# LPC176x5x register map
File version: 0.2
CPU: CM3 r0p0, little endian, no MPU, no FPU, 0x5 interrupt priority bits, 0x0 interrupts
Registers are 32-bit, read-write, no defined reset value unless marked. A register's access mark holds for its fields unless they carry their own. Offsets are from the block's base; [hi:lo] are bit positions.

## EMAC — Ethernet
Base 0x50000000
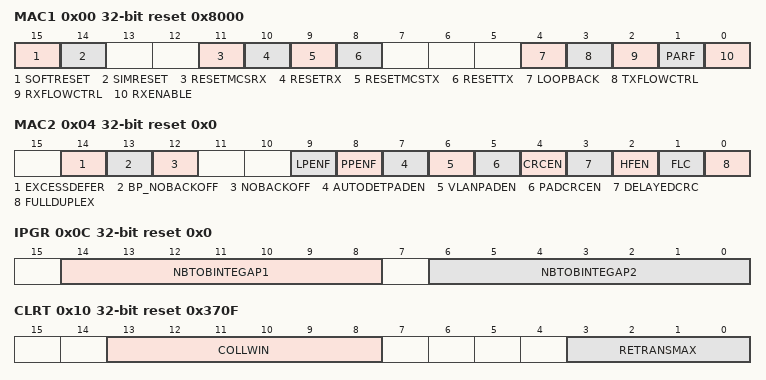
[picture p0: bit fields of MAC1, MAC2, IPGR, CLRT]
0x00 MAC1 reset 0x8000 — MAC configuration register 1.
  [15] SOFTRESET — SOFT RESET. Setting this bit will put all modules within the MAC in reset except the Host Interface.
  [14] SIMRESET — SIMULATION RESET. Setting this bit will cause a reset to the random number generator within the Transmit Function.
  [11] RESETMCSRX — Setting this bit resets the MAC Control Sublayer / Receive logic. The MCS logic implements flow control.
  [10] RESETRX — Setting this bit will put the Ethernet receive logic in reset.
  [9] RESETMCSTX — Setting this bit resets the MAC Control Sublayer / Transmit logic. The MCS logic implements flow control.
  [8] RESETTX — Setting this bit will put the Transmit Function logic in reset.
  [4] LOOPBACK — Setting this bit will cause the MAC Transmit interface to be looped back to the MAC Receive interface. Clearing this bit results in normal operation.
  [3] TXFLOWCTRL — TX FLOW CONTROL. When enabled (set to 1), PAUSE Flow Control frames are allowed to be transmitted. When disabled, Flow Control frames are blocked.
  [2] RXFLOWCTRL — RX FLOW CONTROL. When enabled (set to 1), the MAC acts upon received PAUSE Flow Control frames. When disabled, received PAUSE Flow Control frames are ignored.
  [1] PARF — PASS ALL RECEIVE FRAMES. When enabled (set to 1), the MAC will pass all frames regardless of type (normal vs. Control). When disabled, the MAC does not pass valid Control frames.
  [0] RXENABLE — RECEIVE ENABLE. Set this to allow receive frames to be received. Internally the MAC synchronizes this control bit to the incoming receive stream.
0x04 MAC2 reset 0x0 — MAC configuration register 2.
  [14] EXCESSDEFER — When enabled (set to 1) the MAC will defer to carrier indefinitely as per the Standard. When disabled, the MAC will abort when the excessive deferral limit is reached.
  [13] BP_NOBACKOFF — BACK PRESSURE / NO BACKOFF. When enabled (set to 1), after the MAC incidentally causes a collision during back pressure, it will immediately retransmit without backoff, reducing the chance of further collisions and ensuring transmit packets get sent.
  [12] NOBACKOFF — When enabled (set to 1), the MAC will immediately retransmit following a collision rather than using the Binary Exponential Backoff algorithm as specified in the Standard.
  [9] LPENF — LONG PREAMBLE ENFORCEMENT. When enabled (set to 1), the MAC only allows receive packets which contain preamble fields less than 12 bytes in length. When disabled, the MAC allows any length preamble as per the Standard.
  [8] PPENF — PURE PREAMBLE ENFORCEMEN. When enabled (set to 1), the MAC will verify the content of the preamble to ensure it contains 0x55 and is error-free. A packet with an incorrect preamble is discarded. When disabled, no preamble checking is performed.
  [7] AUTODETPADEN — AUTODETECTPAD ENABLE. Set this bit to cause the MAC to automatically detect the type of frame, either tagged or un-tagged, by comparing the two octets following the source address with 0x8100 (VLAN Protocol ID) and pad accordingly. Table 153 - Pad Operation provides a description of the pad function based on the configuration of this register. Note: This bit is ignored if PAD / CRC ENABLE is cleared.
  [6] VLANPADEN — VLAN PAD ENABLE. Set this bit to cause the MAC to pad all short frames to 64 bytes and append a valid CRC. Consult Table 153 - Pad Operation for more information on the various padding features. Note: This bit is ignored if PAD / CRC ENABLE is cleared.
  [5] PADCRCEN — PAD CRC ENABLE. Set this bit to have the MAC pad all short frames. Clear this bit if frames presented to the MAC have a valid length. This bit is used in conjunction with AUTO PAD ENABLE and VLAN PAD ENABLE. See Table 153 - Pad Operation for details on the pad function.
  [4] CRCEN — CRC ENABLESet this bit to append a CRC to every frame whether padding was required or not. Must be set if PAD/CRC ENABLE is set. Clear this bit if frames presented to the MAC contain a CRC.
  [3] DELAYEDCRC — DELAYED CRC. This bit determines the number of bytes, if any, of proprietary header information that exist on the front of IEEE 802.3 frames. When 1, four bytes of header (ignored by the CRC function) are added. When 0, there is no proprietary header.
  [2] HFEN — HUGE FRAME ENABLEWhen enabled (set to 1), frames of any length are transmitted and received.
  [1] FLC — FRAMELENGTH CHECKING. When enabled (set to 1), both transmit and receive frame lengths are compared to the Length/Type field. If the Length/Type field represents a length then the check is performed. Mismatches are reported in the StatusInfo word for each received frame.
  [0] FULLDUPLEX — When enabled (set to 1), the MAC operates in Full-Duplex mode. When disabled, the MAC operates in Half-Duplex mode.
0x08 IPGT reset 0x0 — Back-to-Back Inter-Packet-Gap register.
  [6:0] BTOBINTEGAP — BACK-TO-BACK INTER-PACKET-GAP.This is a programmable field representing the nibble time offset of the minimum possible period between the end of any transmitted packet to the beginning of the next. In Full-Duplex mode, the register value should be the desired period in nibble times minus 3. In Half-Duplex mode, the register value should be the desired period in nibble times minus 6. In Full-Duplex the recommended setting is 0x15 (21d), which represents the minimum IPG of 960 ns (in 100 Mbps mode) or 9.6 us (in 10 Mbps mode). In Half-Duplex the recommended setting is 0x12 (18d), which also represents the minimum IPG of 960 ns (in 100 Mbps mode) or 9.6 us (in 10 Mbps mode).
0x0C IPGR reset 0x0 — Non Back-to-Back Inter-Packet-Gap register.
  [14:8] NBTOBINTEGAP1 — NON-BACK-TO-BACK INTER-PACKET-GAP PART1. This is a programmable field representing the optional carrierSense window referenced in IEEE 802.3/4.2.3.2.1 'Carrier Deference'. If carrier is detected during the timing of IPGR1, the MAC defers to carrier. If, however, carrier becomes active after IPGR1, the MAC continues timing IPGR2 and transmits, knowingly causing a collision, thus ensuring fair access to medium. Its range of values is 0x0 to IPGR2. The recommended value is 0xC (12d)
  [6:0] NBTOBINTEGAP2 — NON-BACK-TO-BACK INTER-PACKET-GAP PART2. This is a programmable field representing the Non-Back-to-Back Inter-Packet-Gap. The recommended value is 0x12 (18d), which represents the minimum IPG of 960 ns (in 100 Mbps mode) or 9.6 us (in 10 Mbps mode).
0x10 CLRT reset 0x370F — Collision window / Retry register.
  [13:8] COLLWIN — COLLISION WINDOW. This is a programmable field representing the slot time or collision window during which collisions occur in properly configured networks. The default value of 0x37 (55d) represents a 56 byte window following the preamble and SFD.
  [3:0] RETRANSMAX — RETRANSMISSION MAXIMUM.This is a programmable field specifying the number of retransmission attempts following a collision before aborting the packet due to excessive collisions. The Standard specifies the attemptLimit to be 0xF (15d). See IEEE 802.3/4.2.3.2.5.
0x14 MAXF reset 0x600 — Maximum Frame register.
  [15:0] MAXFLEN — MAXIMUM FRAME LENGTH. This field resets to the value 0x0600, which represents a maximum receive frame of 1536 octets. An untagged maximum size Ethernet frame is 1518 octets. A tagged frame adds four octets for a total of 1522 octets. If a shorter maximum length restriction is desired, program this 16-bit field.
0x18 SUPP reset 0x0 — PHY Support register.
  [8] SPEED — This bit configures the Reduced MII logic for the current operating speed. When set, 100 Mbps mode is selected. When cleared, 10 Mbps mode is selected.
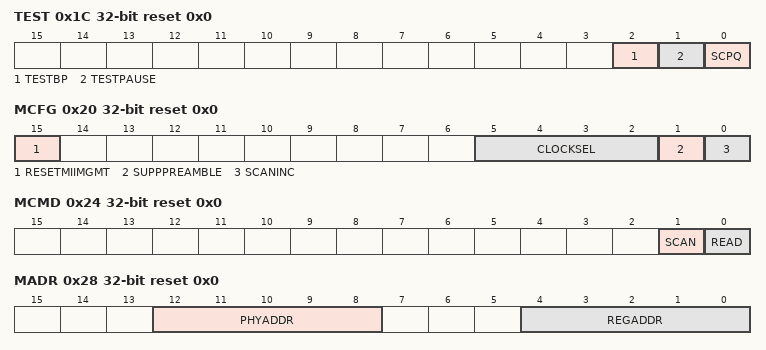
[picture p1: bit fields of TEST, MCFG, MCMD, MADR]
0x1C TEST reset 0x0
  [2] TESTBP — TEST BACKPRESSURE. Setting this bit will cause the MAC to assert backpressure on the link. Backpressure causes preamble to be transmitted, raising carrier sense. A transmit packet from the system will be sent during backpressure.
  [1] TESTPAUSE — This bit causes the MAC Control sublayer to inhibit transmissions, just as if a PAUSE Receive Control frame with a nonzero pause time parameter was received.
  [0] SCPQ — SHORTCUT PAUSE QUANTA. This bit reduces the effective PAUSE quanta from 64 byte-times to 1 byte-time.
0x20 MCFG reset 0x0 — MII Mgmt Configuration register.
  [15] RESETMIIMGMT — RESET MII MGMT. This bit resets the MII Management hardware.
  [5:2] CLOCKSEL — CLOCK SELECT. This field is used by the clock divide logic in creating the MII Management Clock (MDC) which IEEE 802.3u defines to be no faster than 2.5 MHz. Some PHYs support clock rates up to 12.5 MHz, however. The AHB bus clock (HCLK) is divided by the specified amount. Refer to Table 160 below for the definition of values for this field.
  [1] SUPPPREAMBLE — SUPPRESS PREAMBLE. Set this bit to cause the MII Management hardware to perform read/write cycles without the 32-bit preamble field. Clear this bit to cause normal cycles to be performed. Some PHYs support suppressed preamble.
  [0] SCANINC — SCAN INCREMENT. Set this bit to cause the MII Management hardware to perform read cycles across a range of PHYs. When set, the MII Management hardware will perform read cycles from address 1 through the value set in PHY ADDRESS[4:0]. Clear this bit to allow continuous reads of the same PHY.
0x24 MCMD reset 0x0 — MII Mgmt Command register.
  [1] SCAN — This bit causes the MII Management hardware to perform Read cycles continuously. This is useful for monitoring Link Fail for example.
  [0] READ — This bit causes the MII Management hardware to perform a single Read cycle. The Read data is returned in Register MRDD (MII Mgmt Read Data).
0x28 MADR reset 0x0 — MII Mgmt Address register.
  [12:8] PHYADDR — PHY ADDRESS. This field represents the 5-bit PHY Address field of Mgmt cycles. Up to 31 PHYs can be addressed (0 is reserved).
  [4:0] REGADDR — REGISTER ADDRESS. This field represents the 5-bit Register Address field of Mgmt cycles. Up to 32 registers can be accessed.
0x2C MWTD wo reset 0x0 — MII Mgmt Write Data register.
  [15:0] WRITEDATA — WRITE DATA. When written, an MII Mgmt write cycle is performed using the 16-bit data and the pre-configured PHY and Register addresses from the MII Mgmt Address register (MADR).
0x30 MRDD ro reset 0x0 — MII Mgmt Read Data register.
  [15:0] READDATA — READ DATA. Following an MII Mgmt Read Cycle, the 16-bit data can be read from this location.
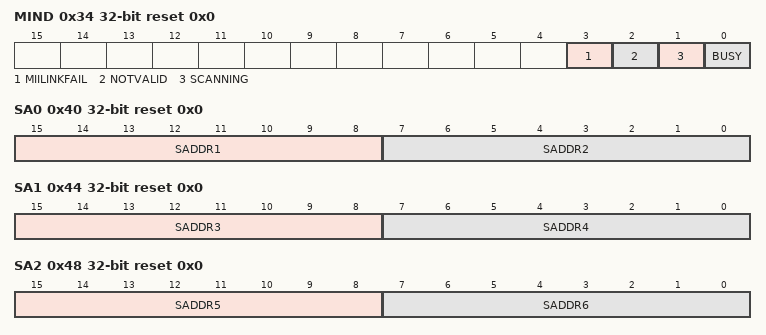
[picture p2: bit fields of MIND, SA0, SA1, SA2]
0x34 MIND ro reset 0x0 — MII Mgmt Indicators register.
  [3] MIILINKFAIL — When 1 is returned - indicates that an MII Mgmt link fail has occurred.
  [2] NOTVALID — When 1 is returned - indicates MII Mgmt Read cycle has not completed and the Read Data is not yet valid.
  [1] SCANNING — When 1 is returned - indicates a scan operation (continuous MII Mgmt Read cycles) is in progress.
  [0] BUSY — When 1 is returned - indicates MII Mgmt is currently performing an MII Mgmt Read or Write cycle.
0x40 SA0 reset 0x0 — Station Address 0 register.
  [15:8] SADDR1 — STATION ADDRESS, 1st octet. This field holds the first octet of the station address.
  [7:0] SADDR2 — STATION ADDRESS, 2nd octet. This field holds the second octet of the station address.
0x44 SA1 reset 0x0 — Station Address 1 register.
  [15:8] SADDR3 — STATION ADDRESS, 3rd octet. This field holds the third octet of the station address.
  [7:0] SADDR4 — STATION ADDRESS, 4th octet. This field holds the fourth octet of the station address.
0x48 SA2 reset 0x0 — Station Address 2 register.
  [15:8] SADDR5 — STATION ADDRESS, 5th octet. This field holds the fifth octet of the station address.
  [7:0] SADDR6 — STATION ADDRESS, 6th octet. This field holds the sixth octet of the station address.
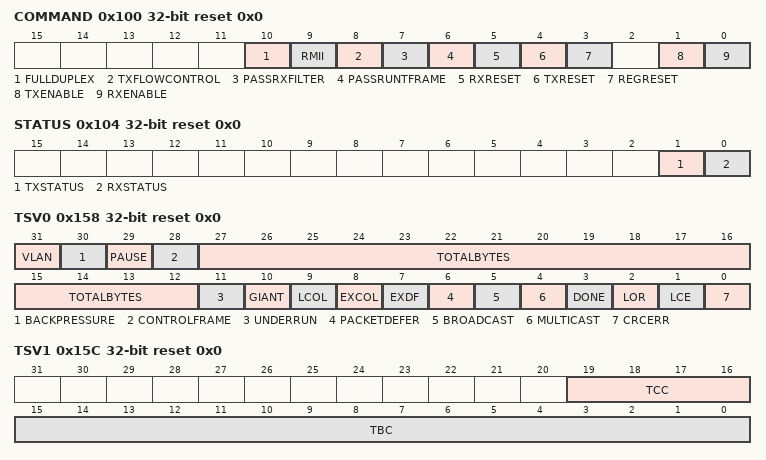
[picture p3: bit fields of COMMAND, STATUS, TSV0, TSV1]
0x100 COMMAND reset 0x0
  [10] FULLDUPLEX — When set to 1 , indicates full duplex operation.
  [9] RMII — When set to 1 , RMII mode is selected; if 0, MII mode is selected.
  [8] TXFLOWCONTROL — Enable IEEE 802.3 / clause 31 flow control sending pause frames in full duplex and continuous preamble in half duplex.
  [7] PASSRXFILTER — When set to 1 , disables receive filtering i.e. all frames received are written to memory.
  [6] PASSRUNTFRAME — When set to 1 , passes runt frames s1maller than 64 bytes to memory unless they have a CRC error. If 0 runt frames are filtered out.
  [5] RXRESET — When a 1 is written, the receive datapath is reset.
  [4] TXRESET — When a 1 is written, the transmit datapath is reset.
  [3] REGRESET — When a 1 is written, all datapaths and the host registers are reset. The MAC needs to be reset separately.
  [1] TXENABLE — Enable transmit.
  [0] RXENABLE — Enable receive.
0x104 STATUS ro reset 0x0
  [1] TXSTATUS — If 1, the transmit channel is active. If 0, the transmit channel is inactive.
  [0] RXSTATUS — If 1, the receive channel is active. If 0, the receive channel is inactive.
0x108 RXDESCRIPTOR reset 0x0 — Receive descriptor base address register.
  [31:2] RXDESCRIPTOR — MSBs of receive descriptor base address.
0x10C RXSTATUS reset 0x0 — Receive status base address register.
  [31:3] RXSTATUS — MSBs of receive status base address.
0x110 RXDESCRIPTORNUMBER reset 0x0 — Receive number of descriptors register.
  [15:0] RXDESCRIPTORN — RxDescriptorNumber. Number of descriptors in the descriptor array for which RxDescriptor is the base address. The number of descriptors is minus one encoded.
0x114 RXPRODUCEINDEX ro reset 0x0 — Receive produce index register.
  [15:0] RXPRODUCEIX — Index of the descriptor that is going to be filled next by the receive datapath.
0x118 RXCONSUMEINDEX reset 0x0 — Receive consume index register.
  [15:0] RXCONSUMEIX — Index of the descriptor that is going to be processed next by the receive
0x11C TXDESCRIPTOR reset 0x0 — Transmit descriptor base address register.
  [31:2] TXD — TxDescriptor. MSBs of transmit descriptor base address.
0x120 TXSTATUS reset 0x0 — Transmit status base address register.
  [31:2] TXSTAT — TxStatus. MSBs of transmit status base address.
0x124 TXDESCRIPTORNUMBER reset 0x0 — Transmit number of descriptors register.
  [15:0] TXDN — TxDescriptorNumber. Number of descriptors in the descriptor array for which TxDescriptor is the base address. The register is minus one encoded.
0x128 TXPRODUCEINDEX reset 0x0 — Transmit produce index register.
  [15:0] TXPI — TxProduceIndex. Index of the descriptor that is going to be filled next by the transmit software driver.
0x12C TXCONSUMEINDEX ro reset 0x0 — Transmit consume index register.
  [15:0] TXCI — TxConsumeIndex. Index of the descriptor that is going to be transmitted next by the transmit datapath.
0x158 TSV0 ro reset 0x0 — Transmit status vector 0 register.
  [31] VLAN — Frame's length/type field contained 0x8100 which is the VLAN protocol identifier.
  [30] BACKPRESSURE — Carrier-sense method backpressure was previously applied.
  [29] PAUSE — The frame was a control frame with a valid PAUSE opcode.
  [28] CONTROLFRAME — The frame was a control frame.
  [27:12] TOTALBYTES — The total number of bytes transferred including collided attempts.
  [11] UNDERRUN — Host side caused buffer underrun.
  [10] GIANT — Byte count in frame was greater than can be represented in the transmit byte count field in TSV1.
  [9] LCOL — Late Collision. Collision occurred beyond collision window, 512 bit times.
  [8] EXCOL — Excessive Collision. Packet was aborted due to exceeding of maximum allowed number of collisions.
  [7] EXDF — Excessive Defer. Packet was deferred in excess of 6071 nibble times in 100 Mbps or 24287 bit times in 10 Mbps mode.
  [6] PACKETDEFER — Packet was deferred for at least one attempt, but less than an excessive defer.
  [5] BROADCAST — Packet's destination was a broadcast address.
  [4] MULTICAST — Packet's destination was a multicast address.
  [3] DONE — Transmission of packet was completed.
  [2] LOR — Length out of range. Indicates that frame type/length field was larger than 1500 bytes. The EMAC doesn't distinguish the frame type and frame length, so, e.g. when the IP(0x8000) or ARP(0x0806) packets are received, it compares the frame type with the max length and gives the "Length out of range" error. In fact, this bit is not an error indication, but simply a statement by the chip regarding the status of the received frame.
  [1] LCE — Length check error. Indicates the frame length field does not match the actual number of data items and is not a type field.
  [0] CRCERR — CRC error. The attached CRC in the packet did not match the internally generated CRC.
0x15C TSV1 ro reset 0x0 — Transmit status vector 1 register.
  [19:16] TCC — Transmit collision count. Number of collisions the current packet incurred during transmission attempts. The maximum number of collisions (16) cannot be represented.
  [15:0] TBC — Transmit byte count. The total number of bytes in the frame, not counting the collided bytes.
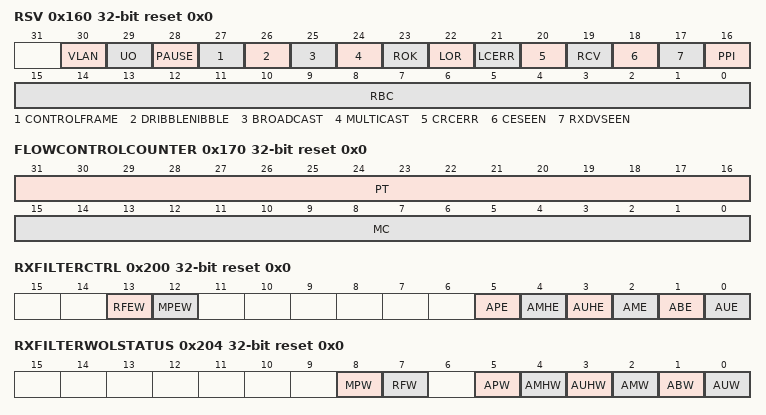
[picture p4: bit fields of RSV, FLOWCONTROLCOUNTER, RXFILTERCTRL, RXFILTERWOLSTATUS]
0x160 RSV ro reset 0x0 — Receive status vector register.
  [30] VLAN — Frame's length/type field contained 0x8100 which is the VLAN protocol identifier.
  [29] UO — Unsupported Opcode. The current frame was recognized as a Control Frame but contains an unknown opcode.
  [28] PAUSE — The frame was a control frame with a valid PAUSE opcode.
  [27] CONTROLFRAME — The frame was a control frame.
  [26] DRIBBLENIBBLE — Indicates that after the end of packet another 1-7 bits were received. A single nibble, called dribble nibble, is formed but not sent out.
  [25] BROADCAST — The packet destination was a broadcast address.
  [24] MULTICAST — The packet destination was a multicast address.
  [23] ROK — Receive OK. The packet had valid CRC and no symbol errors.
  [22] LOR — Length out of range. Indicates that frame type/length field was larger than 1518 bytes. The EMAC doesn't distinguish the frame type and frame length, so, e.g. when the IP(0x8000) or ARP(0x0806) packets are received, it compares the frame type with the max length and gives the "Length out of range" error. In fact, this bit is not an error indication, but simply a statement by the chip regarding the status of the received frame.
  [21] LCERR — Length check error. Indicates the frame length field does not match the actual number of data items and is not a type field.
  [20] CRCERR — CRC error. The attached CRC in the packet did not match the internally generated CRC.
  [19] RCV — Receive code violation. Indicates that received PHY data does not represent a valid receive code.
  [18] CESEEN — Carrier event previously seen. Indicates that at some time since the last receive statistics, a carrier event was detected.
  [17] RXDVSEEN — RXDV event previously seen. Indicates that the last receive event seen was not long enough to be a valid packet.
  [16] PPI — Packet previously ignored. Indicates that a packet was dropped.
  [15:0] RBC — Received byte count. Indicates length of received frame.
0x170 FLOWCONTROLCOUNTER reset 0x0
  [31:16] PT — PauseTimer. In full-duplex mode the PauseTimer specifies the value that is inserted into the pause timer field of a pause flow control frame. In half duplex mode the PauseTimer specifies the number of backpressure cycles.
  [15:0] MC — MirrorCounter. In full duplex mode the MirrorCounter specifies the number of cycles before re-issuing the Pause control frame.
0x174 FLOWCONTROLSTATUS ro reset 0x0
  [15:0] MCC — MirrorCounterCurrent. In full duplex mode this register represents the current value of the datapath's mirror counter which counts up to the value specified by the MirrorCounter field in the FlowControlCounter register. In half duplex mode the register counts until it reaches the value of the PauseTimer bits in the FlowControlCounter register.
0x200 RXFILTERCTRL reset 0x0 — Receive filter control register.
  [13] RFEW — RxFilterEnWoL. When set to 1, the result of the perfect address matching filter and the imperfect hash filter will generate a WoL interrupt when there is a match.
  [12] MPEW — MagicPacketEnWoL. When set to 1, the result of the magic packet filter will generate a WoL interrupt when there is a match.
  [5] APE — AcceptPerfectEn. When set to 1, the frames with a destination address identical to the station address are accepted.
  [4] AMHE — AcceptMulticastHashEn. When set to 1, multicast frames that pass the imperfect hash filter are accepted.
  [3] AUHE — AcceptUnicastHashEn. When set to 1, unicast frames that pass the imperfect hash filter are accepted.
  [2] AME — AcceptMulticastEn. When set to 1, all multicast frames are accepted.
  [1] ABE — AcceptBroadcastEn. When set to 1, all broadcast frames are accepted.
  [0] AUE — AcceptUnicastEn. When set to 1, all unicast frames are accepted.
0x204 RXFILTERWOLSTATUS ro reset 0x0 — Receive filter WoL status register.
  [8] MPW — MagicPacketWoL. When the value is 1, the magic packet filter caused WoL.
  [7] RFW — RxFilterWoL. When the value is 1, the receive filter caused WoL.
  [5] APW — AcceptPerfectWoL. When the value is 1, the perfect address matching filter caused WoL.
  [4] AMHW — AcceptMulticastHashWoL. When the value is 1, a multicast frame that passes the imperfect hash filter caused WoL.
  [3] AUHW — AcceptUnicastHashWoL. When the value is 1, a unicast frame that passes the imperfect hash filter caused WoL.
  [2] AMW — AcceptMulticastWoL. When the value is 1, a multicast frame caused WoL.
  [1] ABW — AcceptBroadcastWoL. When the value is 1, a broadcast frame caused WoL.
  [0] AUW — AcceptUnicastWoL. When the value is 1, a unicast frames caused WoL.
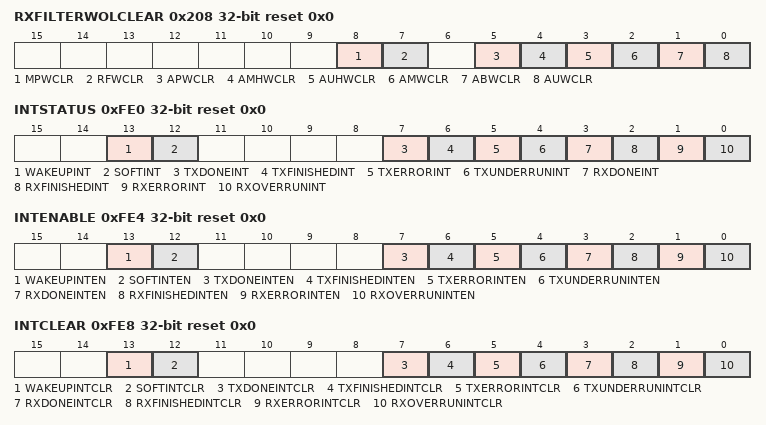
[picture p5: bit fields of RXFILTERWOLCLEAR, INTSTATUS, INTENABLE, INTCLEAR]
0x208 RXFILTERWOLCLEAR wo reset 0x0 — Receive filter WoL clear register.
  [8] MPWCLR — MagicPacketWoLClr. When a 1 is written, the corresponding status bit in the RxFilterWoLStatus register is cleared.
  [7] RFWCLR — RxFilterWoLClr. When a 1 is written, the corresponding status bit in the RxFilterWoLStatus register is cleared.
  [5] APWCLR — AcceptPerfectWoLClr. When a 1 is written, the corresponding status bit in the RxFilterWoLStatus register is cleared.
  [4] AMHWCLR — AcceptMulticastHashWoLClr. When a 1 is written, the corresponding status bit in the RxFilterWoLStatus register is cleared.
  [3] AUHWCLR — AcceptUnicastHashWoLClr. When a 1 is written, the corresponding status bit in the RxFilterWoLStatus register is cleared.
  [2] AMWCLR — AcceptMulticastWoLClr. When a 1 is written, the corresponding status bit in the RxFilterWoLStatus register is cleared.
  [1] ABWCLR — AcceptBroadcastWoLClr. When a 1 is written, the corresponding status bit in the RxFilterWoLStatus register is cleared.
  [0] AUWCLR — AcceptUnicastWoLClr. When a 1 is written, the corresponding status bit in the RxFilterWoLStatus register is cleared.
0x210 HASHFILTERL reset 0x0 — Hash filter table LSBs register.
  [31:0] HFL — HashFilterL. Bits 31:0 of the imperfect filter hash table for receive filtering.
0x214 HASHFILTERH reset 0x0 — Hash filter table MSBs register.
  [31:0] HFH — Bits 63:32 of the imperfect filter hash table for receive filtering.
0xFE0 INTSTATUS ro reset 0x0 — Interrupt status register.
  [13] WAKEUPINT — Interrupt triggered by a Wake-up event detected by the receive filter.
  [12] SOFTINT — Interrupt triggered by software writing a 1 to the SoftIntSet bit in the IntSet register.
  [7] TXDONEINT — Interrupt triggered when a descriptor has been transmitted while the Interrupt bit in the Control field of the descriptor was set.
  [6] TXFINISHEDINT — Interrupt triggered when all transmit descriptors have been processed i.e. on the transition to the situation where ProduceIndex == ConsumeIndex.
  [5] TXERRORINT — Interrupt trigger on transmit errors: LateCollision, ExcessiveCollision and ExcessiveDefer, NoDescriptor or Underrun.
  [4] TXUNDERRUNINT — Interrupt set on a fatal underrun error in the transmit queue. The fatal interrupt should be resolved by a Tx soft-reset. The bit is not set when there is a nonfatal underrun error.
  [3] RXDONEINT — Interrupt triggered when a receive descriptor has been processed while the Interrupt bit in the Control field of the descriptor was set.
  [2] RXFINISHEDINT — Interrupt triggered when all receive descriptors have been processed i.e. on the transition to the situation where ProduceIndex == ConsumeIndex.
  [1] RXERRORINT — Interrupt trigger on receive errors: AlignmentError, RangeError, LengthError, SymbolError, CRCError or NoDescriptor or Overrun.
  [0] RXOVERRUNINT — Interrupt set on a fatal overrun error in the receive queue. The fatal interrupt should be resolved by a Rx soft-reset. The bit is not set when there is a nonfatal overrun error.
0xFE4 INTENABLE reset 0x0 — Interrupt enable register.
  [13] WAKEUPINTEN — Enable for interrupt triggered by a Wake-up event detected by the receive filter.
  [12] SOFTINTEN — Enable for interrupt triggered by the SoftInt bit in the IntStatus register, caused by software writing a 1 to the SoftIntSet bit in the IntSet register.
  [7] TXDONEINTEN — Enable for interrupt triggered when a descriptor has been transmitted while the Interrupt bit in the Control field of the descriptor was set.
  [6] TXFINISHEDINTEN — Enable for interrupt triggered when all transmit descriptors have been processed i.e. on the transition to the situation where ProduceIndex == ConsumeIndex.
  [5] TXERRORINTEN — Enable for interrupt trigger on transmit errors.
  [4] TXUNDERRUNINTEN — Enable for interrupt trigger on transmit buffer or descriptor underrun situations.
  [3] RXDONEINTEN — Enable for interrupt triggered when a receive descriptor has been processed while the Interrupt bit in the Control field of the descriptor was set.
  [2] RXFINISHEDINTEN — Enable for interrupt triggered when all receive descriptors have been processed i.e. on the transition to the situation where ProduceIndex == ConsumeIndex.
  [1] RXERRORINTEN — Enable for interrupt trigger on receive errors.
  [0] RXOVERRUNINTEN — Enable for interrupt trigger on receive buffer overrun or descriptor underrun situations.
0xFE8 INTCLEAR wo reset 0x0 — Interrupt clear register.
  [13] WAKEUPINTCLR — Writing a 1 clears the corresponding status bit in interrupt status register IntStatus.
  [12] SOFTINTCLR — Writing a 1 clears the corresponding status bit in interrupt status register IntStatus.
  [7] TXDONEINTCLR — Writing a 1 clears the corresponding status bit in interrupt status register IntStatus.
  [6] TXFINISHEDINTCLR — Writing a 1 clears the corresponding status bit in interrupt status register IntStatus.
  [5] TXERRORINTCLR — Writing a 1 clears the corresponding status bit in interrupt status register IntStatus.
  [4] TXUNDERRUNINTCLR — Writing a 1 clears the corresponding status bit in interrupt status register IntStatus.
  [3] RXDONEINTCLR — Writing a 1 clears the corresponding status bit in interrupt status register IntStatus.
  [2] RXFINISHEDINTCLR — Writing a 1 clears the corresponding status bit in interrupt status register IntStatus.
  [1] RXERRORINTCLR — Writing a 1 clears the corresponding status bit in interrupt status register IntStatus.
  [0] RXOVERRUNINTCLR — Writing a 1 clears the corresponding status bit in interrupt status register IntStatus.
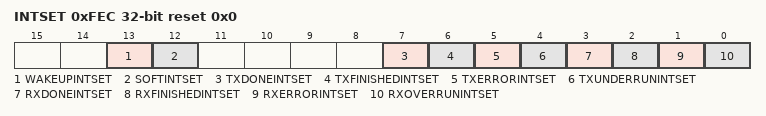
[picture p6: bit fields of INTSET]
0xFEC INTSET wo reset 0x0 — Interrupt set register.
  [13] WAKEUPINTSET — Writing a 1 to one sets the corresponding status bit in interrupt status register IntStatus.
  [12] SOFTINTSET — Writing a 1 to one sets the corresponding status bit in interrupt status register IntStatus.
  [7] TXDONEINTSET — Writing a 1 to one sets the corresponding status bit in interrupt status register IntStatus.
  [6] TXFINISHEDINTSET — Writing a 1 to one sets the corresponding status bit in interrupt status register IntStatus.
  [5] TXERRORINTSET — Writing a 1 to one sets the corresponding status bit in interrupt status register IntStatus.
  [4] TXUNDERRUNINTSET — Writing a 1 to one sets the corresponding status bit in interrupt status register IntStatus.
  [3] RXDONEINTSET — Writing a 1 to one sets the corresponding status bit in interrupt status register IntStatus.
  [2] RXFINISHEDINTSET — Writing a 1 to one sets the corresponding status bit in interrupt status register IntStatus.
  [1] RXERRORINTSET — Writing a 1 to one sets the corresponding status bit in interrupt status register IntStatus.
  [0] RXOVERRUNINTSET — Writing a 1 to one sets the corresponding status bit in interrupt status register IntStatus.
0xFF4 POWERDOWN reset 0x0
  [31] PD — PowerDownMACAHB. If true, all AHB accesses will return a read/write error, except accesses to the Power-Down register.
